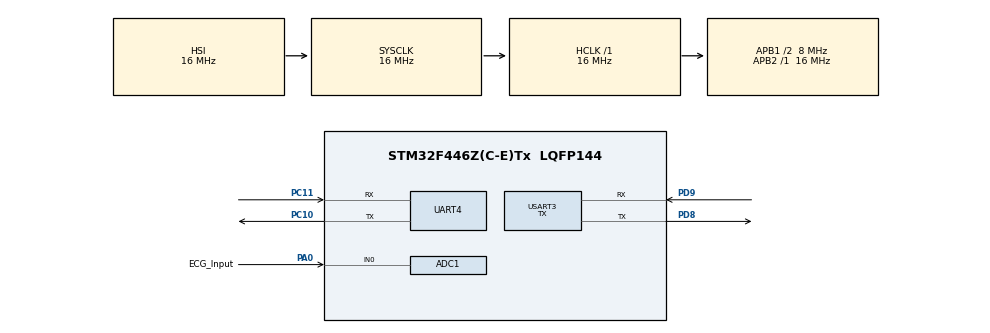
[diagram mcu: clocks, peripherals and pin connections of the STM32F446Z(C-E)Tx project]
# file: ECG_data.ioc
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ADC1.Channel-0\#ChannelRegularConversion=ADC_CHANNEL_0
ADC1.NbrOfConversionFlag=1
ADC1.Rank-0\#ChannelRegularConversion=1
ADC1.SamplingTime-0\#ChannelRegularConversion=ADC_SAMPLETIME_3CYCLES
ADC1.master=1
Mcu.Family=STM32F4
Mcu.Name=STM32F446Z(C-E)Tx
Mcu.Package=LQFP144
NVIC.PriorityGroup=NVIC_PRIORITYGROUP_4
NVIC.UART4_IRQn=true\:0\:0\:false\:false\:true\:true\:true\:true
PA0-WKUP.GPIO_Label=ECG_Input
PA0-WKUP.Signal=ADCx_IN0
PA13.Mode=Serial_Wire
PA13.Signal=SYS_JTMS-SWDIO
PA14.Mode=Serial_Wire
PA14.Signal=SYS_JTCK-SWCLK
PC10.Mode=Asynchronous
PC10.Signal=UART4_TX
PC11.Mode=Asynchronous
PC11.Signal=UART4_RX
PC14-OSC32_IN.Mode=LSE-External-Clock-Source
PC14-OSC32_IN.Signal=RCC_OSC32_IN
PC15-OSC32_OUT.Mode=LSE-External-Clock-Source
PC15-OSC32_OUT.Signal=RCC_OSC32_OUT
PD8.Mode=Asynchronous
PD8.Signal=USART3_TX
PD9.Mode=Asynchronous
PD9.Signal=USART3_RX
PH0-OSC_IN.Mode=HSE-External-Oscillator
PH0-OSC_IN.Signal=RCC_OSC_IN
PH1-OSC_OUT.Mode=HSE-External-Oscillator
PH1-OSC_OUT.Signal=RCC_OSC_OUT
ProjectManager.HeapSize=0x200
ProjectManager.StackSize=0x400
ProjectManager.TargetToolchain=STM32CubeIDE
RCC.48MHZClocksFreq_Value=24000000
RCC.AHBFreq_Value=16000000
RCC.APB1CLKDivider=RCC_HCLK_DIV2
RCC.APB1Freq_Value=8000000
RCC.APB1TimFreq_Value=16000000
RCC.APB2Freq_Value=16000000
RCC.APB2TimFreq_Value=16000000
RCC.CortexFreq_Value=16000000
RCC.HCLKFreq_Value=16000000
RCC.HSE_VALUE=8000000
RCC.HSI_VALUE=16000000
RCC.LSE_VALUE=32768
RCC.PLLMUL=RCC_PLL_MUL9
RCC.PRESCALERUSB=RCC_USBCLKSOURCE_PLL_DIV1_5
RCC.SYSCLKFreq_VALUE=16000000
RCC.SYSCLKSourceVirtual=RCC_SYSCLKSOURCE_PLLCLK
RCC.USBFreq_Value=96000000
RCC.VCOOutputFreq_Value=192000000
SH.ADCx_IN0.0=ADC1_IN0,IN0
UART4.VirtualMode=Asynchronous
USART3.Mode=MODE_TX
USART3.VirtualMode=VM_ASYNC
board=NUCLEO-F446ZE

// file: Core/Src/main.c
/* USER CODE BEGIN Header */
/**
  ******************************************************************************
  * @file           : main.c
  * @brief          : Main program body
  ******************************************************************************
  * @attention
  *
  * Copyright (c) 2024 STMicroelectronics.
  * All rights reserved.
  *
  * This software is licensed under terms that can be found in the LICENSE file
  * in the root directory of this software component.
  * If no LICENSE file comes with this software, it is provided AS-IS.
  *
  ******************************************************************************
  */
/* USER CODE END Header */
#include "main.h"

ADC_HandleTypeDef hadc1;

UART_HandleTypeDef huart4;
UART_HandleTypeDef huart3;

/* USER CODE BEGIN PV */
uint32_t value_adc;
/* USER CODE END PV */

void SystemClock_Config(void);
static void MX_GPIO_Init(void);
static void MX_ADC1_Init(void);
static void MX_UART4_Init(void);
static void MX_USART3_UART_Init(void);

int main(void)
{

  /* MCU Configuration--------------------------------------------------------*/

  /* Reset of all peripherals, Initializes the Flash interface and the Systick. */
  HAL_Init();

  /* Configure the system clock */
  SystemClock_Config();

  /* Initialize all configured peripherals */
  MX_GPIO_Init();
  MX_ADC1_Init();
  MX_UART4_Init();
  MX_USART3_UART_Init();
  /* USER CODE BEGIN 2 */
  unsigned char* next = 'a';
  /* USER CODE END 2 */

  /* Infinite loop */
  /* USER CODE BEGIN WHILE */
  while (1)
  {
	 HAL_ADC_Start(&hadc1);
	 if(HAL_ADC_PollForConversion(&hadc1, HAL_MAX_DELAY)==HAL_OK){
	 value_adc = HAL_ADC_GetValue(&hadc1);
	 HAL_UART_Transmit(&huart3, (uint8_t*)(value_adc), sizeof(value_adc), 10);
	 //HAL_UART_Transmit(&huart4, value_adc, sizeof(value_adc), 10);
	 HAL_UART_Transmit(&huart3, next, 1, 100);
	 }
	 HAL_ADC_Stop(&hadc1);
    /* USER CODE END WHILE */

  }
}

void SystemClock_Config(void)
{
  RCC_OscInitTypeDef RCC_OscInitStruct = {0};
  RCC_ClkInitTypeDef RCC_ClkInitStruct = {0};

  /** Configure the main internal regulator output voltage
  */
  __HAL_RCC_PWR_CLK_ENABLE();
  __HAL_PWR_VOLTAGESCALING_CONFIG(PWR_REGULATOR_VOLTAGE_SCALE3);

  /** Initializes the RCC Oscillators according to the specified parameters
  * in the RCC_OscInitTypeDef structure.
  */
  RCC_OscInitStruct.OscillatorType = RCC_OSCILLATORTYPE_HSI;
  RCC_OscInitStruct.HSIState = RCC_HSI_ON;
  RCC_OscInitStruct.HSICalibrationValue = RCC_HSICALIBRATION_DEFAULT;
  RCC_OscInitStruct.PLL.PLLState = RCC_PLL_NONE;
  if (HAL_RCC_OscConfig(&RCC_OscInitStruct) != HAL_OK)
  {
    Error_Handler();
  }

  /** Initializes the CPU, AHB and APB buses clocks
  */
  RCC_ClkInitStruct.ClockType = RCC_CLOCKTYPE_HCLK|RCC_CLOCKTYPE_SYSCLK
                              |RCC_CLOCKTYPE_PCLK1|RCC_CLOCKTYPE_PCLK2;
  RCC_ClkInitStruct.SYSCLKSource = RCC_SYSCLKSOURCE_HSI;
  RCC_ClkInitStruct.AHBCLKDivider = RCC_SYSCLK_DIV1;
  RCC_ClkInitStruct.APB1CLKDivider = RCC_HCLK_DIV2;
  RCC_ClkInitStruct.APB2CLKDivider = RCC_HCLK_DIV1;

  if (HAL_RCC_ClockConfig(&RCC_ClkInitStruct, FLASH_LATENCY_0) != HAL_OK)
  {
    Error_Handler();
  }
}

static void MX_ADC1_Init(void)
{

  ADC_ChannelConfTypeDef sConfig = {0};

  /** Configure the global features of the ADC (Clock, Resolution, Data Alignment and number of conversion)
  */
  hadc1.Instance = ADC1;
  hadc1.Init.ClockPrescaler = ADC_CLOCK_SYNC_PCLK_DIV2;
  hadc1.Init.Resolution = ADC_RESOLUTION_12B;
  hadc1.Init.ScanConvMode = DISABLE;
  hadc1.Init.ContinuousConvMode = DISABLE;
  hadc1.Init.DiscontinuousConvMode = DISABLE;
  hadc1.Init.ExternalTrigConvEdge = ADC_EXTERNALTRIGCONVEDGE_NONE;
  hadc1.Init.ExternalTrigConv = ADC_SOFTWARE_START;
  hadc1.Init.DataAlign = ADC_DATAALIGN_RIGHT;
  hadc1.Init.NbrOfConversion = 1;
  hadc1.Init.DMAContinuousRequests = DISABLE;
  hadc1.Init.EOCSelection = ADC_EOC_SINGLE_CONV;
  if (HAL_ADC_Init(&hadc1) != HAL_OK)
  {
    Error_Handler();
  }

  /** Configure for the selected ADC regular channel its corresponding rank in the sequencer and its sample time.
  */
  sConfig.Channel = ADC_CHANNEL_0;
  sConfig.Rank = 1;
  sConfig.SamplingTime = ADC_SAMPLETIME_3CYCLES;
  if (HAL_ADC_ConfigChannel(&hadc1, &sConfig) != HAL_OK)
  {
    Error_Handler();
  }

}

static void MX_UART4_Init(void)
{

  huart4.Instance = UART4;
  huart4.Init.BaudRate = 115200;
  huart4.Init.WordLength = UART_WORDLENGTH_8B;
  huart4.Init.StopBits = UART_STOPBITS_1;
  huart4.Init.Parity = UART_PARITY_NONE;
  huart4.Init.Mode = UART_MODE_TX_RX;
  huart4.Init.HwFlowCtl = UART_HWCONTROL_NONE;
  huart4.Init.OverSampling = UART_OVERSAMPLING_16;
  if (HAL_UART_Init(&huart4) != HAL_OK)
  {
    Error_Handler();
  }

}

static void MX_USART3_UART_Init(void)
{

  huart3.Instance = USART3;
  huart3.Init.BaudRate = 115200;
  huart3.Init.WordLength = UART_WORDLENGTH_8B;
  huart3.Init.StopBits = UART_STOPBITS_1;
  huart3.Init.Parity = UART_PARITY_NONE;
  huart3.Init.Mode = UART_MODE_TX;
  huart3.Init.HwFlowCtl = UART_HWCONTROL_NONE;
  huart3.Init.OverSampling = UART_OVERSAMPLING_16;
  if (HAL_UART_Init(&huart3) != HAL_OK)
  {
    Error_Handler();
  }

}

static void MX_GPIO_Init(void)
{

  /* GPIO Ports Clock Enable */
  __HAL_RCC_GPIOC_CLK_ENABLE();
  __HAL_RCC_GPIOH_CLK_ENABLE();
  __HAL_RCC_GPIOA_CLK_ENABLE();
  __HAL_RCC_GPIOD_CLK_ENABLE();

}

void Error_Handler(void)
{
  __disable_irq();
  while (1)
  {
  }
}
